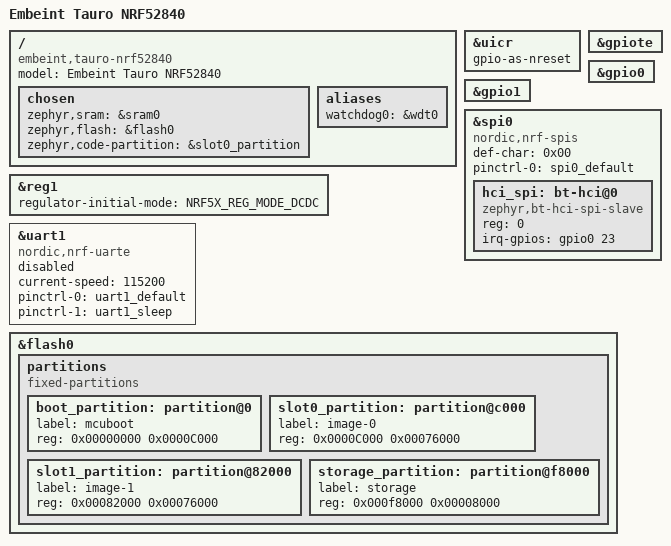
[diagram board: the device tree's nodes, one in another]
/*
 * Copyright (c) 2024 Embeint Holdings Pty Ltd
 *
 * SPDX-License-Identifier: Apache-2.0
 */

/dts-v1/;
#include <nordic/nrf52840_qiaa.dtsi>
#include "tauro_nrf52840-pinctrl.dtsi"

/ {
	model = "Embeint Tauro NRF52840";
	compatible = "embeint,tauro-nrf52840";

	chosen {
		zephyr,sram = &sram0;
		zephyr,flash = &flash0;
		zephyr,code-partition = &slot0_partition;
	};

	aliases {
		watchdog0 = &wdt0;
	};
};

&uicr {
	gpio-as-nreset;
};

&reg1 {
	regulator-initial-mode = <NRF5X_REG_MODE_DCDC>;
};

&gpiote {
	status = "okay";
};

&gpio0 {
	status = "okay";
};

&gpio1 {
	status = "okay";
};

&spi0 {
	compatible = "nordic,nrf-spis";
	status = "okay";
	def-char = <0x00>;
	pinctrl-0 = <&spi0_default>;
	pinctrl-names = "default";

	hci_spi: bt-hci@0 {
		compatible = "zephyr,bt-hci-spi-slave";
		reg = <0>;
		irq-gpios = <&gpio0 23 GPIO_ACTIVE_HIGH>;
		/* Additional GPIO is available here:
		 * extra-gpios = <&gpio0 22 0>;
		 */
	};
};

&uart1 {
	compatible = "nordic,nrf-uarte";
	current-speed = <115200>;
	status = "disabled";
	pinctrl-0 = <&uart1_default>;
	pinctrl-1 = <&uart1_sleep>;
	pinctrl-names = "default", "sleep";
};

&flash0 {

	partitions {
		compatible = "fixed-partitions";
		#address-cells = <1>;
		#size-cells = <1>;

		boot_partition: partition@0 {
			label = "mcuboot";
			reg = <0x00000000 0x0000C000>;
		};
		slot0_partition: partition@c000 {
			label = "image-0";
			reg = <0x0000C000 0x00076000>;
		};
		slot1_partition: partition@82000 {
			label = "image-1";
			reg = <0x00082000 0x00076000>;
		};

		/*
		 * The flash starting at 0x000f8000 and ending at
		 * 0x000fffff is reserved for use by the application.
		 */

		/*
		 * Storage partition will be used by FCB/LittleFS/NVS
		 * if enabled.
		 */
		storage_partition: partition@f8000 {
			label = "storage";
			reg = <0x000f8000 0x00008000>;
		};
	};
};
